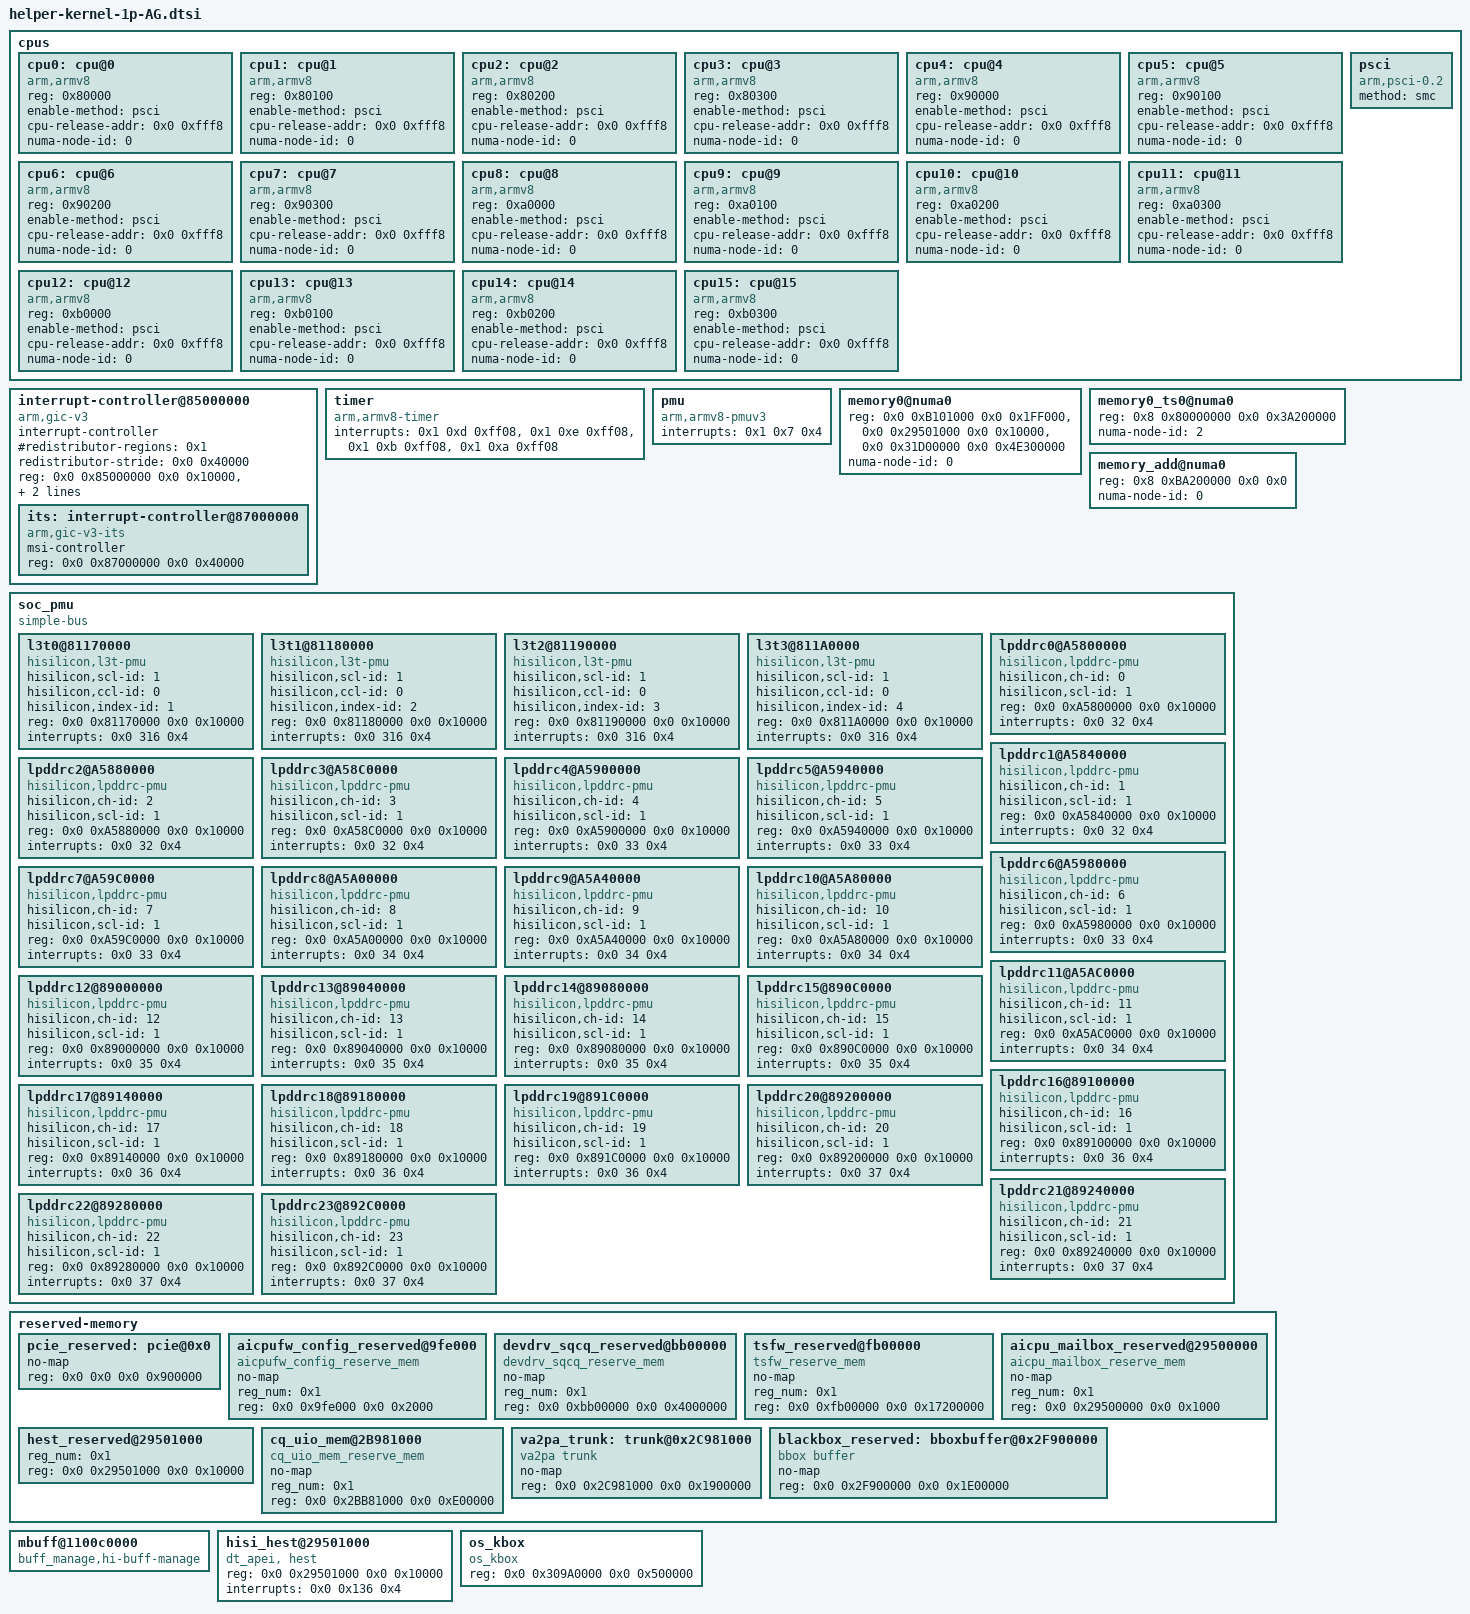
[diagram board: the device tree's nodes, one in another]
/**
* dts file for Hisilicon Ascend Dxxx Development Board
*
* Copyright (C) 2020 Hisilicon Ltd.
*
* This program is free software; you can redistribute it and/or modify
* it under the terms of the GNU General Public License version 2 as
* publishhed by the Free Software Foundation.
*
* Owner：OS
* Author:  c00283067
* Create: Sun Apr 26 19:04:57 CST 2020
*/
    cpus {
        #address-cells = <0x1>;
        #size-cells = <0x0>;

        cpu0:cpu@0 {
            device_type = "cpu";
            compatible = "arm,armv8";
            reg = <0x80000>;
            enable-method = "psci";
            cpu-release-addr = <0x0 0xfff8>;
            numa-node-id = <0>;
        };

	cpu1:cpu@1 {
	    device_type = "cpu";
            compatible = "arm,armv8";
            reg = <0x80100>;
            enable-method = "psci";
            cpu-release-addr = <0x0 0xfff8>;
            numa-node-id = <0>;
	};

	cpu2:cpu@2 {
	    device_type = "cpu";
            compatible = "arm,armv8";
            reg = <0x80200>;
            enable-method = "psci";
            cpu-release-addr = <0x0 0xfff8>;
            numa-node-id = <0>;
	};

	cpu3:cpu@3 {
	    device_type = "cpu";
            compatible = "arm,armv8";
            reg = <0x80300>;
            enable-method = "psci";
            cpu-release-addr = <0x0 0xfff8>;
            numa-node-id = <0>;
	};

	cpu4:cpu@4 {
	    device_type = "cpu";
	    compatible = "arm,armv8";
	    reg = <0x90000>;
	    enable-method = "psci";
	    cpu-release-addr = <0x0 0xfff8>;
            numa-node-id = <0>;
	};

	cpu5:cpu@5 {
	    device_type = "cpu";
	    compatible = "arm,armv8";
	    reg = <0x90100>;
	    enable-method = "psci";
	    cpu-release-addr = <0x0 0xfff8>;
            numa-node-id = <0>;
	};

	cpu6:cpu@6 {
	    device_type = "cpu";
	    compatible = "arm,armv8";
	    reg = <0x90200>;
	    enable-method = "psci";
	    cpu-release-addr = <0x0 0xfff8>;
            numa-node-id = <0>;
	};

	cpu7:cpu@7 {
	    device_type = "cpu";
	    compatible = "arm,armv8";
	    reg = <0x90300>;
	    enable-method = "psci";
            cpu-release-addr = <0x0 0xfff8>;
            numa-node-id = <0>;
	};

        cpu8:cpu@8 {
            device_type = "cpu";
            compatible = "arm,armv8";
            reg = <0xa0000>;
            enable-method = "psci";
            cpu-release-addr = <0x0 0xfff8>;
            numa-node-id = <0>;
        };

	cpu9:cpu@9 {
	    device_type = "cpu";
            compatible = "arm,armv8";
            reg = <0xa0100>;
            enable-method = "psci";
            cpu-release-addr = <0x0 0xfff8>;
            numa-node-id = <0>;
	};

	cpu10:cpu@10 {
	    device_type = "cpu";
            compatible = "arm,armv8";
            reg = <0xa0200>;
            enable-method = "psci";
            cpu-release-addr = <0x0 0xfff8>;
            numa-node-id = <0>;
	};

	cpu11:cpu@11 {
	    device_type = "cpu";
            compatible = "arm,armv8";
            reg = <0xa0300>;
            enable-method = "psci";
            cpu-release-addr = <0x0 0xfff8>;
            numa-node-id = <0>;
	};

	cpu12:cpu@12 {
	    device_type = "cpu";
	    compatible = "arm,armv8";
	    reg = <0xb0000>;
	    enable-method = "psci";
	    cpu-release-addr = <0x0 0xfff8>;
            numa-node-id = <0>;
	};

	cpu13:cpu@13 {
	    device_type = "cpu";
	    compatible = "arm,armv8";
	    reg = <0xb0100>;
	    enable-method = "psci";
	    cpu-release-addr = <0x0 0xfff8>;
            numa-node-id = <0>;
	};

	cpu14:cpu@14 {
	    device_type = "cpu";
	    compatible = "arm,armv8";
	    reg = <0xb0200>;
	    enable-method = "psci";
	    cpu-release-addr = <0x0 0xfff8>;
            numa-node-id = <0>;
	};

	cpu15:cpu@15 {
	    device_type = "cpu";
	    compatible = "arm,armv8";
	    reg = <0xb0300>;
	    enable-method = "psci";
            cpu-release-addr = <0x0 0xfff8>;
            numa-node-id = <0>;
	};

        psci {
            compatible = "arm,psci-0.2";
            method = "smc";
        };
    };

    interrupt-controller@85000000 {
        compatible = "arm,gic-v3";
        #interrupt-cells = <0x3>;
        #address-cells = <0x2>;
        #size-cells = <0x2>;
        ranges;
        interrupt-controller;
        #redistributor-regions = <0x1>;
        redistributor-stride = <0x0 0x40000>;
        reg = <0x0 0x85000000 0x0 0x10000>,    /* GICD */
              <0x0 0x85100000 0x0 0x800000>;    /* GICR1: CPUS 0-31 */
        interrupts = <0x1 0x9 0xff04>;
        linux,phandle = <0x1>;
        phandle = <0x1>;

        its: interrupt-controller@87000000 {
            compatible = "arm,gic-v3-its";
            msi-controller;
            #msi-cells = <0x1>;
            reg = <0x0 0x87000000 0x0 0x40000>;
        };
    };

    timer {
        compatible = "arm,armv8-timer";
        interrupts = <0x1 0xd 0xff08>,    /* secure */
                     <0x1 0xe 0xff08>,    /* non-secure */
                     <0x1 0xb 0xff08>,    /* virtual */
                     <0x1 0xa 0xff08>;    /* hypervisor */
    };

    pmu {
	compatible = "arm,armv8-pmuv3";
	interrupts = <0x1 0x7 0x4>;
    };


    memory0@numa0 {
        device_type = "memory";
        reg = <0x0 0xB101000 0x0 0x1FF000>, //For log_redirect
              <0x0 0x29501000 0x0 0x10000>, //For apei table
              <0x0 0x31D00000 0x0 0x4E300000>; // for dma32
        numa-node-id = <0>;
    };

    memory0_ts0@numa0 {
        device_type = "memory";
        reg = <0x8 0x80000000 0x0 0x3A200000>;
        numa-node-id = <2>;
    };

    memory_add@numa0 {
        device_type = "memory";
        reg = <0x8 0xBA200000 0x0 0x0>;
        numa-node-id = <0>;  // node0 for OS
    };

    soc_pmu {
        compatible = "simple-bus";
        #address-cells = <0x2>;
        #size-cells = <0x2>;
        ranges;

        l3t0@81170000 {
            compatible = "hisilicon,l3t-pmu";
			hisilicon,scl-id = <1>;
			hisilicon,ccl-id = <0>;
			hisilicon,index-id = <1>;
            reg = <0x0 0x81170000 0x0 0x10000>;
			interrupts = <0x0 316 0x4>;
		};

        l3t1@81180000 {
            compatible = "hisilicon,l3t-pmu";
			hisilicon,scl-id = <1>;
			hisilicon,ccl-id = <0>;
			hisilicon,index-id = <2>;
            reg = <0x0 0x81180000 0x0 0x10000>;
			interrupts = <0x0 316 0x4>;
		};

        l3t2@81190000 {
            compatible = "hisilicon,l3t-pmu";
			hisilicon,scl-id = <1>;
			hisilicon,ccl-id = <0>;
			hisilicon,index-id = <3>;
            reg = <0x0 0x81190000 0x0 0x10000>;
			interrupts = <0x0 316 0x4>;
		};

        l3t3@811A0000 {
            compatible = "hisilicon,l3t-pmu";
			hisilicon,scl-id = <1>;
			hisilicon,ccl-id = <0>;
			hisilicon,index-id = <4>;
            reg = <0x0 0x811A0000 0x0 0x10000>;
			interrupts = <0x0 316 0x4>;
		};

		lpddrc0@A5800000 {
            compatible = "hisilicon,lpddrc-pmu";
            hisilicon,ch-id = <0>;
			hisilicon,scl-id = <1>;
            reg = <0x0 0xA5800000 0x0 0x10000>;
			interrupts = <0x0 32 0x4>;
        };

        lpddrc1@A5840000 {
            compatible = "hisilicon,lpddrc-pmu";
			hisilicon,ch-id = <1>;
			hisilicon,scl-id = <1>;
            reg = <0x0 0xA5840000 0x0 0x10000>;
			interrupts = <0x0 32 0x4>;
        };

        lpddrc2@A5880000 {
            compatible = "hisilicon,lpddrc-pmu";
			hisilicon,ch-id = <2>;
            hisilicon,scl-id = <1>;
            reg = <0x0 0xA5880000 0x0 0x10000>;
			interrupts = <0x0 32 0x4>;
        };

        lpddrc3@A58C0000 {
            compatible = "hisilicon,lpddrc-pmu";
            hisilicon,ch-id = <3>;
			hisilicon,scl-id = <1>;
            reg = <0x0 0xA58C0000 0x0 0x10000>;
			interrupts = <0x0 32 0x4>;
        };

        lpddrc4@A5900000 {
            compatible = "hisilicon,lpddrc-pmu";
            hisilicon,ch-id = <4>;
			hisilicon,scl-id = <1>;
            reg = <0x0 0xA5900000 0x0 0x10000>;
			interrupts = <0x0 33 0x4>;
        };

        lpddrc5@A5940000 {
            compatible = "hisilicon,lpddrc-pmu";
            hisilicon,ch-id = <5>;
			hisilicon,scl-id = <1>;
            reg = <0x0 0xA5940000 0x0 0x10000>;
			interrupts = <0x0 33 0x4>;
        };

        lpddrc6@A5980000 {
            compatible = "hisilicon,lpddrc-pmu";
            hisilicon,ch-id = <6>;
			hisilicon,scl-id = <1>;
            reg = <0x0 0xA5980000 0x0 0x10000>;
			interrupts = <0x0 33 0x4>;
        };

        lpddrc7@A59C0000 {
            compatible = "hisilicon,lpddrc-pmu";
            hisilicon,ch-id = <7>;
			hisilicon,scl-id = <1>;
            reg = <0x0 0xA59C0000 0x0 0x10000>;
			interrupts = <0x0 33 0x4>;
        };

        lpddrc8@A5A00000 {
            compatible = "hisilicon,lpddrc-pmu";
            hisilicon,ch-id = <8>;
			hisilicon,scl-id = <1>;
            reg = <0x0 0xA5A00000 0x0 0x10000>;
			interrupts = <0x0 34 0x4>;
        };

        lpddrc9@A5A40000 {
            compatible = "hisilicon,lpddrc-pmu";
            hisilicon,ch-id = <9>;
			hisilicon,scl-id = <1>;
            reg = <0x0 0xA5A40000 0x0 0x10000>;
			interrupts = <0x0 34 0x4>;
        };

        lpddrc10@A5A80000 {
            compatible = "hisilicon,lpddrc-pmu";
            hisilicon,ch-id = <10>;
			hisilicon,scl-id = <1>;
            reg = <0x0 0xA5A80000 0x0 0x10000>;
			interrupts = <0x0 34 0x4>;
        };

        lpddrc11@A5AC0000 {
            compatible = "hisilicon,lpddrc-pmu";
            hisilicon,ch-id = <11>;
			hisilicon,scl-id = <1>;
            reg = <0x0 0xA5AC0000 0x0 0x10000>;
			interrupts = <0x0 34 0x4>;
        };

        lpddrc12@89000000 {
            compatible = "hisilicon,lpddrc-pmu";
            hisilicon,ch-id = <12>;
			hisilicon,scl-id = <1>;
            reg = <0x0 0x89000000 0x0 0x10000>;
			interrupts = <0x0 35 0x4>;
        };

        lpddrc13@89040000 {
            compatible = "hisilicon,lpddrc-pmu";
            hisilicon,ch-id = <13>;
			hisilicon,scl-id = <1>;
            reg = <0x0 0x89040000 0x0 0x10000>;
			interrupts = <0x0 35 0x4>;
        };

        lpddrc14@89080000 {
            compatible = "hisilicon,lpddrc-pmu";
            hisilicon,ch-id = <14>;
			hisilicon,scl-id = <1>;
            reg = <0x0 0x89080000 0x0 0x10000>;
			interrupts = <0x0 35 0x4>;
        };

        lpddrc15@890C0000 {
            compatible = "hisilicon,lpddrc-pmu";
            hisilicon,ch-id = <15>;
			hisilicon,scl-id = <1>;
            reg = <0x0 0x890C0000 0x0 0x10000>;
			interrupts = <0x0 35 0x4>;
        };

        lpddrc16@89100000 {
            compatible = "hisilicon,lpddrc-pmu";
            hisilicon,ch-id = <16>;
			hisilicon,scl-id = <1>;
            reg = <0x0 0x89100000 0x0 0x10000>;
			interrupts = <0x0 36 0x4>;
        };

        lpddrc17@89140000 {
            compatible = "hisilicon,lpddrc-pmu";
            hisilicon,ch-id = <17>;
			hisilicon,scl-id = <1>;
            reg = <0x0 0x89140000 0x0 0x10000>;
			interrupts = <0x0 36 0x4>;
        };

        lpddrc18@89180000 {
            compatible = "hisilicon,lpddrc-pmu";
            hisilicon,ch-id = <18>;
			hisilicon,scl-id = <1>;
            reg = <0x0 0x89180000 0x0 0x10000>;
			interrupts = <0x0 36 0x4>;
        };

        lpddrc19@891C0000 {
            compatible = "hisilicon,lpddrc-pmu";
            hisilicon,ch-id = <19>;
			hisilicon,scl-id = <1>;
            reg = <0x0 0x891C0000 0x0 0x10000>;
			interrupts = <0x0 36 0x4>;
        };

        lpddrc20@89200000 {
            compatible = "hisilicon,lpddrc-pmu";
            hisilicon,ch-id = <20>;
			hisilicon,scl-id = <1>;
            reg = <0x0 0x89200000 0x0 0x10000>;
			interrupts = <0x0 37 0x4>;
        };

        lpddrc21@89240000 {
            compatible = "hisilicon,lpddrc-pmu";
            hisilicon,ch-id = <21>;
			hisilicon,scl-id = <1>;
            reg = <0x0 0x89240000 0x0 0x10000>;
			interrupts = <0x0 37 0x4>;
        };

        lpddrc22@89280000 {
            compatible = "hisilicon,lpddrc-pmu";
            hisilicon,ch-id = <22>;
			hisilicon,scl-id = <1>;
            reg = <0x0 0x89280000 0x0 0x10000>;
			interrupts = <0x0 37 0x4>;
        };

        lpddrc23@892C0000 {
            compatible = "hisilicon,lpddrc-pmu";
            hisilicon,ch-id = <23>;
			hisilicon,scl-id = <1>;
            reg = <0x0 0x892C0000 0x0 0x10000>;
			interrupts = <0x0 37 0x4>;
        };
    };

    reserved-memory {
        #address-cells = <0x2>;
        #size-cells = <0x2>;
        ranges;

        pcie_reserved: pcie@0x0 {
            no-map;
            reg = <0x0 0x0 0x0 0x900000>;
        };

        aicpufw_config_reserved@9fe000 {
            compatible = "aicpufw_config_reserve_mem";
            no-map;
            reg_num = <0x1>;
            reg = <0x0 0x9fe000 0x0 0x2000>;
        };

        devdrv_sqcq_reserved@bb00000 {
            compatible = "devdrv_sqcq_reserve_mem";
            no-map;
            reg_num = <0x1>;
            reg = <0x0 0xbb00000 0x0 0x4000000>;
        };

        tsfw_reserved@fb00000 {
            compatible = "tsfw_reserve_mem";
            no-map;
            reg_num = <0x1>;
            reg = <0x0 0xfb00000 0x0 0x17200000>;
        };

        aicpu_mailbox_reserved@29500000 {
            compatible = "aicpu_mailbox_reserve_mem";
            no-map;
            reg_num = <0x1>;
            reg = <0x0 0x29500000 0x0 0x1000>;
        };

        hest_reserved@29501000 {
            reg_num = <0x1>;
            reg = <0x0 0x29501000 0x0 0x10000>;
        };

        cq_uio_mem@2B981000 {
            compatible = "cq_uio_mem_reserve_mem";
            no-map;
            reg_num = <0x1>;
            reg = <0x0 0x2BB81000 0x0 0xE00000>;
        };

        va2pa_trunk: trunk@0x2C981000 {
            compatible = "va2pa trunk";
            no-map;
            reg = <0x0 0x2C981000 0x0 0x1900000>;
        };

        blackbox_reserved: bboxbuffer@0x2F900000 {
            compatible = "bbox buffer";
            no-map;
            reg = <0x0 0x2F900000 0x0 0x1E00000>;
        };
    };

    mbuff@1100c0000 {
        compatible = "buff_manage,hi-buff-manage";
    };

    hisi_hest@29501000 {
        compatible = "dt_apei, hest";
        reg = <0x0 0x29501000 0x0 0x10000>;
        /* type:  0: SPI
         * num:   342
         * Trig type 04:high
         */
        interrupts = <0x0 0x136 0x4>;
    };

    os_kbox {
        compatible = "os_kbox";
        reg = <0x0 0x309A0000 0x0 0x500000>;
    };
